AUTOSAR XML (schema 4-2-2)
package /AUTOLIV/SoftwareComponents/OsIf
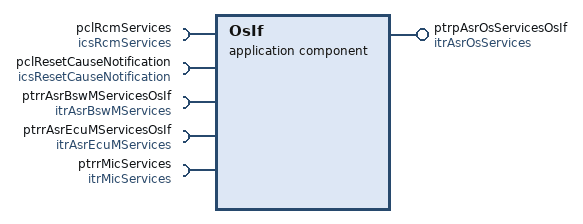
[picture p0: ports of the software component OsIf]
  application sw component type OsIf: category=BSW_Operating_System
    require port pclRcmServices: client-com-spec=ReportOsErrorStatus, required-interface=icsRcmServices  # # Architecture Element ID ARCH_SW_OsIf_pclRcmServices_ErrorHook # Description - The report OS error status runnable shall be called in order to signal to the RCM module what kind of OS exception has occured - The {OS Error Task Id} parameter shall represent the task on which an OS exception has occured - The {OS Error Code} parameter shall represent the OS exception type # Data Flow ## Outputs - {OS Error Task Id} - {OS Error Code} # Linked Runnable - ErrorHook #Traceability #--------------------------------------------------------------------------------------------------------------------------------------------- # Architecture Element ID ARCH_SW_OsIf_pclRcmServices_ProtectionHook # Description - The report OS error status runnable shall be called in order to signal to the RCM module what kind of OS exception has occured - The {OS Error Task Id} parameter shall represent the task on which an OS exception has occured - The {OS Error Code} parameter shall represent the OS exception type # Data Flow ## Outputs - {OS Error Task Id} - {OS Error Code} # Linked Runnable - ProtectionHook #Traceability
    require port pclResetCauseNotification: client-com-spec=NotifyResetCause, required-interface=icsResetCauseNotification  # # Architecture Element ID ARCH_SW_OsIf_pclResetCauseNotification_ErrorHook # Description - The reset cause notification shall be called in order to signal to the RCM module that an reset has occured - The {Reset Cause Notification} parameter shall represent the type of reset that has occured (KU32_OS_EXCEPTION_NOTIFICATION) - The {Reset Cause Status} parameter shall represent the current status of the reset notification # Data Flow ## Outputs - {Reset Cause Notification} - {Reset Cause Status} - Can be: KU32_RESET_CAUSE_ACTIVE, KU32_RESET_CAUSE_INACTIVE # Linked Runnable - ErrorHook #Traceability #--------------------------------------------------------------------------------------------------------------------------------------------- # Architecture Element ID ARCH_SW_OsIf_pclResetCauseNotification_ProtectionHook # Description - The reset cause notification shall be called in order to signal to the RCM module that an reset has occured - The {Reset Cause Notification} parameter shall represent the type of reset that has occured (KU32_OS_EXCEPTION_NOTIFICATION) - The {Reset Cause Status} parameter shall represent the current status of the reset notification # Data Flow ## Outputs - {Reset Cause Notification} - {Reset Cause Status} - Can be: KU32_RESET_CAUSE_ACTIVE, KU32_RESET_CAUSE_INACTIVE # Linked Runnable - ProtectionHook #Traceability
    provide port ptrpAsrOsServicesOsIf: provided-interface=itrAsrOsServices  # # Architecture Element ID ARCH_SW_OsIf_ptrpAsrOsServices_OsTask_Bsw_Init # Description - The OsTask_Bsw_Init runnable shall be called during the initialization by the Autosar Os # Data Flow #Linked Runnable - OsTask_Bsw_Init # Traceability ------------------------------------------------------------------------------------------------ # Architecture Element ID ARCH_SW_OsIf_ptrpAsrOsServices_ErrorHook # Description - The ErrorHook runnable shall be called by the Autosar Os in case of a protection violation is detected unless the error was caused within ProtectionHook() # Data Flow #Linked Runnable - ErrorHook # Traceability ------------------------------------------------------------------------------------------------ # Architecture Element ID ARCH_SW_OsIf_ptrpAsrOsServices_ProtectionHook # Description - The ProtectionHook runnable shall be called by the Autosar Os whenever an error is detected unless the error was caused within ErrorHook() # Data Flow #Linked Runnable - ProtectionHook # Traceability
    require port ptrrAsrBswMServicesOsIf: required-interface=itrAsrBswMServices  # # Architecture Element ID ARCH_SW_OsIf_ptrrAsrBswMServices # Description - The BswM_RequestMode runnable shall be called during the initialization in the OsTask_Bsw_Init runnable in order to signal that the Startup Two A phase can begin (Autosar compliant) # Data Flow #Linked Runnable - OsTask_Bsw_Init # Traceability
    require port ptrrAsrEcuMServicesOsIf: required-interface=itrAsrEcuMServices  # # Architecture Element ID ARCH_SW_OsIf_ptrrAsrEcuMServices # Description - The EcuM_StartupTwo runnable shall be called during the initialization in the OsTask_Bsw_Init runnable # Data Flow #Linked Runnable - OsTask_Bsw_Init # Traceability
    require port ptrrMicServices: required-interface=itrMicServices  # # Architecture Element ID ARCH_SW_OsIf_ptrrMicServices # Description - The MIC_HardFaultException runnable shall be called if the ProtectionHook runnable was called by the OS with the OS_E_EXCEPTPROT error Id - The MIC_BusFaultException runnable shall be called if the ProtectionHook runnable was called by the OS with the OS_E_MEMPROT error Id # Data Flow ## Inputs ## Outputs # Linked Runnable - ProtectionHook #Traceability
